# S6E1B3xG register map
Vendor: Cypress; File version: 2.1
CPU: CM0PLUS r0p1, little endian, no MPU, no FPU, 2 interrupt priority bits
Registers are 8-bit, read-write, reset 0x0 unless marked. A register's access mark holds for its fields unless they carry their own. Offsets are from the block's base; [hi:lo] are bit positions; {n}, {i} and the like mark numbered series.

## LVD — Low-voltage Detection
Base 0x40035000
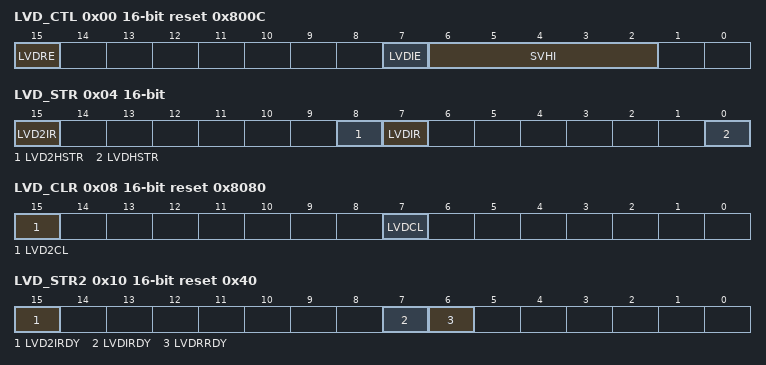
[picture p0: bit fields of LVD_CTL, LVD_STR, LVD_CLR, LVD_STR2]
0x00 LVD_CTL 16-bit reset 0x800C — Low-voltage Detection Voltage Control Register [BHW]
  [15] LVDRE — Low-voltage detection reset operation enable bit
  [7] LVDIE — Low-voltage detection interrupt enable bit
  [6:2] SVHI — Low-voltage detection interrupt voltage setting bits
0x04 LVD_STR 16-bit ro — Low-voltage Detection Interrupt Factor Register [BHW]
  [15] LVD2IR — Low-voltage detection 2 interrupt factor bit
  [8] LVD2HSTR — Voltage of VCC is higher than the setting of SVH2RLI
  [7] LVDIR — Low-voltage detection interrupt factor bit
  [0] LVDHSTR — Voltage of VCC is higher than the setting of SVHRLI
0x08 LVD_CLR 16-bit reset 0x8080 — Low-voltage Detection Interrupt Factor Clear Register [BHW]
  [15] LVD2CL — Low-voltage detection 2 interrupt factor clear bit
  [7] LVDCL — Low-voltage detection interrupt factor clear bit
0x0C LVD_RLR 32-bit reset 0x1 — Low-voltage Detection Voltage Protection Register [W]
  [31:0] LVDLCK — Low-voltage Detection Voltage Control Register protection bits
0x10 LVD_STR2 16-bit ro reset 0x40 — Low-voltage Detection Circuit Status Register [BHW]
  [15] LVD2IRDY — Low-voltage detection 2 interrupt status flag
  [7] LVDIRDY — Low-voltage detection interrupt status flag
  [6] LVDRRDY — Low-voltage detection reset status flag
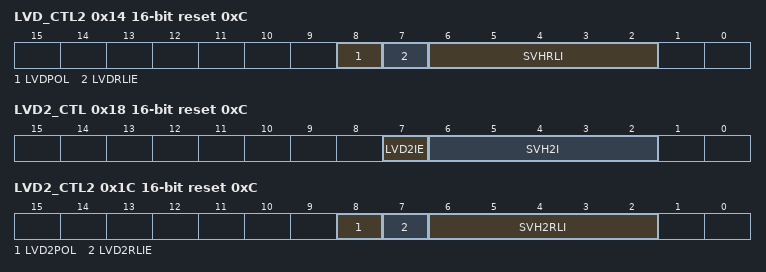
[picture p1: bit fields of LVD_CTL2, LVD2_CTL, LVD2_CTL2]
0x14 LVD_CTL2 16-bit reset 0xC — Low-voltage Detection Release Voltage Control Register [BHW]
  [8] LVDPOL — Low-voltage detection polarity setting bit
  [7] LVDRLIE — Low-voltage detection release voltage setting enable bit
  [6:2] SVHRLI — Low-voltage detection release voltage setting bits
0x18 LVD2_CTL 16-bit reset 0xC — Low-Voltage Detection Channel 2 Voltage Control Register [BHW]
  [7] LVD2IE — Low-voltage detection 2 interrupt enable bit
  [6:2] SVH2I — Low-voltage detection 2 interrupt voltage setting bits
0x1C LVD2_CTL2 16-bit reset 0xC — Low-Voltage Detection Channel 2 Release Voltage Control Register [BHW]
  [8] LVD2POL — Low-voltage detection 2 polarity setting bits
  [7] LVD2RLIE — Low-voltage detection 2 release voltage setting enable bit
  [6:2] SVH2RLI — Low-voltage detection 2 release voltage setting bits

## DS — Low Power Consumption Mode Registers
Base 0x40035100
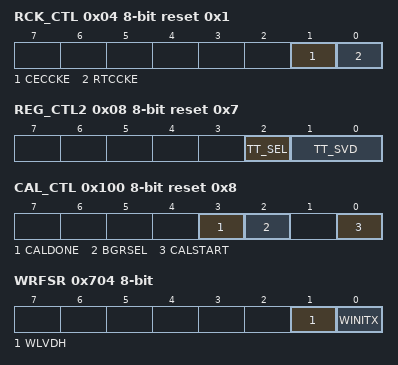
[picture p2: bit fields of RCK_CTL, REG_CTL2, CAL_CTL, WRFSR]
0x04 RCK_CTL reset 0x1 — Sub Clock Control Register [BHW]
  [1] CECCKE — CEC clock control bit
  [0] RTCCKE — RTC clock control bit
0x08 REG_CTL2 reset 0x7 — Internal Voltage Control Register [BHW]
  [2] TT_SEL — Function enable bit
  [1:0] TT_SVD — Internalvoltage setting bit
0x10 MOSC_CTL reset 0x4 — Main Oscillation Crystal Type Selection Control Register [BHW]
  [2:1] IMAINSEL — Main oscillation circuit current setting bits
0x100 CAL_CTL reset 0x8 — Vref Calibration Control Register [BHW]
  [3] CALDONE ro — Vref Calibration Done Flag
  [2] BGRSEL — Vref Select Bit
  [0] CALSTART — Vref Calibration Start Bit
0x104 CAL_SET reset 0x11 — Vref Calibration Value Register [BHW]
  [4:0] DSTB — Vref Calibration Value
0x108 CAL_KEY 32-bit reset 0x1 — Vref Calibration Security Key Register [W]
0x700 PMD_CTL — RTC Mode Control Register [BHW]
  [0] RTCE — RTC mode control bit
0x704 WRFSR ro — Deep Standby Return Factor Register 1 [BHW]
  [1] WLVDH — Low-voltage detection reset return bit
  [0] WINITX — INITX pin input reset return bit
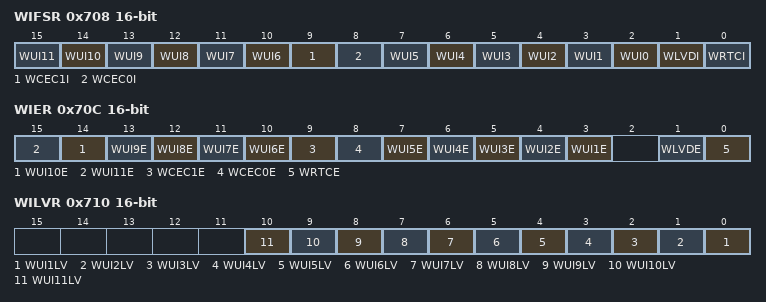
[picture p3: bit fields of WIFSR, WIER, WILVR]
0x708 WIFSR 16-bit ro — Deep Standby Return Factor Register 2 [BHW]
  [n+4] WUI{n} (n=6..11) — WKUP{n} pin input return bit
  [9] WCEC1I — CEC ch.1 interrupt return bit
  [8] WCEC0I — CEC ch.0 interrupt return bit
  [n+2] WUI{n} (n=0..5) — WKUP{n} pin input return bit
  [1] WLVDI — LVD interrupt return bit
  [0] WRTCI — RTC interrupt return bit
0x70C WIER 16-bit — Deep Standby Return Enable Register [BHW]
  [n+4] WUI{n}E ro (n=6..11) — WKUP{n} pin input return enable bit
  [9] WCEC1E — HDMI-CEC/ Remote Control Reception ch.1 interrupt return enable bit
  [8] WCEC0E — HDMI-CEC/ Remote Control Reception ch.0 interrupt return enable bit
  [n+2] WUI{n}E (n=1..5) — WKUP{n} pin input return enable bit
  [1] WLVDE — LVD interrupt return enable bit
  [0] WRTCE — RTC interrupt return enable bit
0x710 WILVR 16-bit — WKUP Pin Input Level Register [BHW]
  [n-1] WUI{n}LV (n=1..11) — WKUP{n} pin input level select bit
0x714 DSRAMR — Deep Standby RAM Retention Register [BHW]
  [1:0] SRAMR — On-chip SRAM retention control bits
0x720 STBFLASHPDX — Flash Power Down In Stop/Rtc/Sub Timer Mode Register [BHW]
  [0] STBFLASHPDX — Flash Power Down in Stop/Rtc/Sub Timer Mode Bit
{0x7FF+i} BUR{i:02} (i=1..16) — Backup Register {i:02} [BHW]
